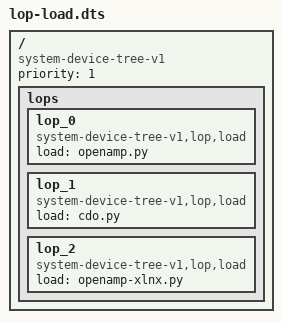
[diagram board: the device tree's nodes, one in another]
/dts-v1/;

/ {
        compatible = "system-device-tree-v1";
        // this means run it first
        priority = <1>;
        lops {
                lop_0 {
                        compatible = "system-device-tree-v1,lop,load";
                        load = "openamp.py";
                };
                lop_1 {
                        compatible = "system-device-tree-v1,lop,load";
                        load = "cdo.py";
                };
                lop_2 {
                        compatible = "system-device-tree-v1,lop,load";
                        load = "openamp-xlnx.py";
                };
        };
};
